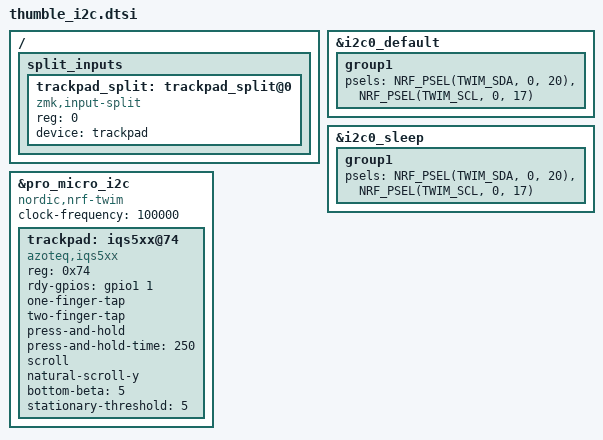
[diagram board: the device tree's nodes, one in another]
/*
 * Azoteq TPS65 trackpad (IQS550, driven by the community azoteq,iqs5xx driver).
 *
 * Wiring on the Thumble: SDA/SCL/3V3/GND come through the VIK connector (the
 * PCB has 3v3 pull-ups R1/R2). The VIK GP pins are NOT routed to the
 * nice!nano, so RDY is bodge-wired to P1.01 (the wire the Cirque DR used).
 * RST is not connected; the driver skips the reset pulse when reset-gpios is
 * absent. RDY is mandatory: the driver only reads the pad when RDY rises.
 *
 * The TPS65's cable/breakout crosses SDA and SCL relative to the VIK pinout
 * (confirmed on hardware: the pad only ACKs at 0x74 with the lines swapped),
 * so the swap is done here in firmware: SDA on P0.20, SCL on P0.17.
 */

&i2c0_default {
    group1 {
        psels = <NRF_PSEL(TWIM_SDA, 0, 20)>,
                <NRF_PSEL(TWIM_SCL, 0, 17)>;
    };
};

&i2c0_sleep {
    group1 {
        psels = <NRF_PSEL(TWIM_SDA, 0, 20)>,
                <NRF_PSEL(TWIM_SCL, 0, 17)>;
    };
};

&pro_micro_i2c {
    /*
     * The nice!nano defaults i2c0 to the legacy TWI driver; TWIM does the
     * IQS5xx's register reads (16-bit address write, repeated START, read)
     * as one EasyDMA transfer. The board's pinctrl already uses the
     * TWIM_SDA/TWIM_SCL functions.
     */
    compatible = "nordic,nrf-twim";
    /*
     * 100 kHz instead of the board's 400 kHz: at 400 kHz the nRF52840 TWIM's
     * SCL low time is marginal (anomaly 219), and through the TPS65 cable
     * reads intermittently failed with -EIO. A full IQS5xx report is a handful
     * of short transfers, well inside the 13 ms active report period at 100k.
     */
    clock-frequency = <100000>;
    status = "okay";

    trackpad: iqs5xx@74 {
        compatible = "azoteq,iqs5xx";
        reg = <0x74>;
        status = "okay";
        rdy-gpios = <&gpio1 1 (GPIO_ACTIVE_HIGH | GPIO_PULL_DOWN)>;

        /* gestures */
        one-finger-tap;
        two-finger-tap;
        press-and-hold;
        press-and-hold-time = <250>;
        scroll;
        natural-scroll-y;

        /*
         * tuning: 10 / 2 was tried for slow-speed accuracy and felt floaty on
         * hardware, so these stay at 5 / 5.
         */
        bottom-beta = <5>;
        stationary-threshold = <5>;

        /* orientation: uncomment as needed once you see how it tracks */
        // flip-x;
        // flip-y;
        // switch-xy;
    };
};

/*
 * Forward trackpad input over the split link. The dongle declares the
 * matching endpoint (same reg) plus the input-listener; a listener must NOT
 * also live here, or the peripheral would try to act as a mouse itself.
 */
/ {
    split_inputs {
        #address-cells = <1>;
        #size-cells = <0>;

        trackpad_split: trackpad_split@0 {
            compatible = "zmk,input-split";
            reg = <0>;
            device = <&trackpad>;
        };
    };
};
